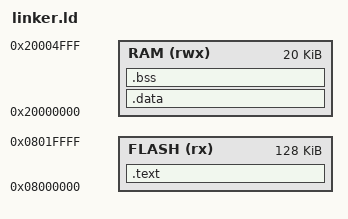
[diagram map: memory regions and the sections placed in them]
ENTRY(reset_handler)

MEMORY
{
	FLASH (rx) : ORIGIN = 0x08000000, LENGTH = 128K
	RAM (rwx) : ORIGIN = 0x20000000, LENGTH = 20K
}

SECTIONS
{
	.text :
	{
		KEEP(*(.isr_vector))
		_modules_init_start = .;
		*(.modules_init*)
		_modules_init_end = .;
		*(.text)
		*(.text.*)
		*(.rodata)
		*(.rodata.*)
		_sromdev = .;
		_eromdev = .;
		_sidata = .;
	} >FLASH

	.data : AT(_sidata)
	{
		_sdata = .;
		*(.data)
		*(.data*)
		_edata = .;
	} >RAM

	.bss :
	{
		_sbss = .;
		*(.bss)
		_ebss = .;
	} >RAM

	_estack = ORIGIN(RAM) + LENGTH(RAM);
}
